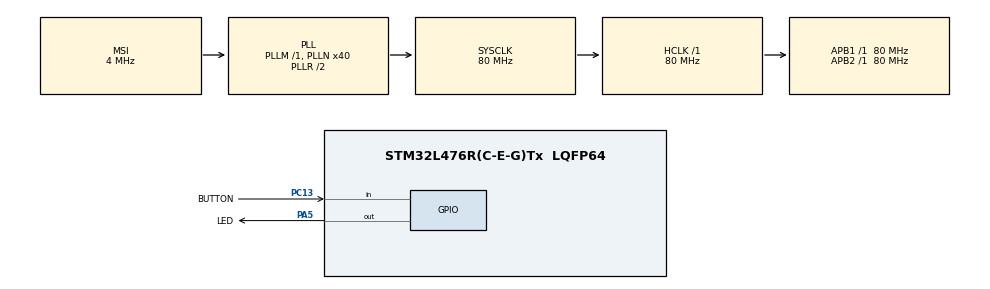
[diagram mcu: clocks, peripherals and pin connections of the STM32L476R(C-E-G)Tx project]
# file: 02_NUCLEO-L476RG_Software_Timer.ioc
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Mcu.Family=STM32L4
Mcu.Name=STM32L476R(C-E-G)Tx
Mcu.Package=LQFP64
Mcu.UserConstants=TIMER_PRESCALER,7999;TIMER_COUNTER,9
NVIC.PriorityGroup=NVIC_PRIORITYGROUP_4
NVIC.TIM6_DAC_IRQn=true\:0\:0\:false\:false\:true\:true\:true
PA5.GPIO_Label=LED
PA5.Signal=GPIO_Output
PC13.GPIO_Label=BUTTON
PC13.Signal=GPIO_Input
ProjectManager.HeapSize=0x200
ProjectManager.StackSize=0x400
ProjectManager.TargetToolchain=STM32CubeIDE
RCC.AHBFreq_Value=80000000
RCC.APB1Freq_Value=80000000
RCC.APB1TimFreq_Value=80000000
RCC.APB2Freq_Value=80000000
RCC.APB2TimFreq_Value=80000000
RCC.CortexFreq_Value=80000000
RCC.HCLKFreq_Value=80000000
RCC.HSE_VALUE=8000000
RCC.HSI_VALUE=16000000
RCC.LSE_VALUE=32768
RCC.MSI_VALUE=4000000
RCC.PLLN=40
RCC.SYSCLKFreq_VALUE=80000000
RCC.SYSCLKSource=RCC_SYSCLKSOURCE_PLLCLK
RCC.VCOOutputFreq_Value=160000000
TIM6.Period=TIMER_COUNTER
TIM6.Prescaler=TIMER_PRESCALER
VP_TIM6_VS_ClockSourceINT.Mode=Enable_Timer
board=custom

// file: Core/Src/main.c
/* USER CODE BEGIN Header */
/**
  ******************************************************************************
  * @file           : main.c
  * @brief          : Main program body
  ******************************************************************************
  * @attention
  *
  * <h2><center>&copy; Copyright (c) 2020 STMicroelectronics.
  * All rights reserved.</center></h2>
  *
  * This software component is licensed by ST under BSD 3-Clause license,
  * the "License"; You may not use this file except in compliance with the
  * License. You may obtain a copy of the License at:
  *                        opensource.org/licenses/BSD-3-Clause
  *
  ******************************************************************************
  */
/* USER CODE END Header */

#include "main.h"
#include "tim.h"
#include "gpio.h"

/* USER CODE BEGIN Includes */
#include "common.h"
#include "software_timer.h"

/* USER CODE END Includes */

/* USER CODE BEGIN PD */
#define APP 4
#if APP == 1
	#define LED_BLINKING_APP		// Software timer array for LED blinking
#elif APP == 2
	#define BUZZER_SOUND_APP		// Software timer for press button and buzzer sound
#elif APP == 3
	#define LCD_BACKLIGHT_APP		// Software timer for LCD backlight ON
#elif APP == 4
	#define UART_TIMEOUT_APP		// Software timer for UART receive timeout
#endif
/* USER CODE END PD */

/* USER CODE BEGIN PV */
#ifdef LED_BLINKING_APP
uint8_t ledSoftwareTimerId[NUM_OF_SOFTWARE_TIMER / 2];
bool ledSoftwareTimerToggle[NUM_OF_SOFTWARE_TIMER / 2];
#endif

#ifdef BUZZER_SOUND_APP
bool isButtonPressed;
uint8_t buzzerTimerId;
bool isBuzzerOn;
#endif

#ifdef LCD_BACKLIGHT_APP
bool isButtonPressed;
uint8_t lcdBackLightTimerId;
bool isBackLightOn;
#endif

#ifdef UART_TIMEOUT_APP
bool isButtonPressed;
uint8_t uartReceiveTimeoutTimerId;
bool isUartReceiveTimeout;
bool isUartAcceptReceive;
#endif
/* USER CODE END PV */

void SystemClock_Config(void);

/* USER CODE BEGIN 0 */
#ifdef LED_BLINKING_APP
/*******************************************************************************
 * @fn      LedTimerCallback
 * @brief   LED timer Callback
 * @paramz  softwareTimerId
 * @return  None
 ******************************************************************************/
void LedTimerCallback(uint8_t softwareTimerId)
{
	ledSoftwareTimerToggle[softwareTimerId] = !ledSoftwareTimerToggle[softwareTimerId];
}
#endif

#ifdef BUZZER_SOUND_APP
/*******************************************************************************
 * @fn      BuzzerTimerStartCallback
 * @brief   Buzzer timer start callback
 * @paramz  softwareTimerId
 * @return  None
 ******************************************************************************/
void BuzzerTimerStartCallback(uint8_t softwareTimerId)
{
	// BuzzerOn();
	isBuzzerOn = true;
	HAL_GPIO_WritePin(LED_GPIO_Port, LED_Pin, GPIO_PIN_SET);
}

/*******************************************************************************
 * @fn      BuzzerTimerCallback
 * @brief   Buzzer timer callback
 * @paramz  softwareTimerId
 * @return  None
 ******************************************************************************/
void BuzzerTimerCallback(uint8_t softwareTimerId)
{
	// BuzzerOff();
	isBuzzerOn = false;
	HAL_GPIO_WritePin(LED_GPIO_Port, LED_Pin, GPIO_PIN_RESET);
}
#endif

#ifdef LCD_BACKLIGHT_APP
/*******************************************************************************
 * @fn      BackLightTimerStartCallback
 * @brief   Back light timer start callback
 * @paramz  softwareTimerId
 * @return  None
 ******************************************************************************/
void BackLightTimerStartCallback(uint8_t softwareTimerId)
{
	// BackLightOn();
	isBackLightOn = true;
}

/*******************************************************************************
 * @fn      BackLightTimerCallback
 * @brief   Back light timer callback
 * @paramz  softwareTimerId
 * @return  None
 ******************************************************************************/
void BackLightTimerCallback(uint8_t softwareTimerId)
{
	// BackLightOff();
	isBackLightOn = false;
}
#endif

#ifdef UART_TIMEOUT_APP
/*******************************************************************************
 * @fn      UartReceiveTimeoutTimerStartCallback
 * @brief   Uart receive timeout timer start callback
 * @paramz  softwareTimerId
 * @return  None
 ******************************************************************************/
void UartReceiveTimeoutTimerStartCallback(uint8_t softwareTimerId)
{
	isUartReceiveTimeout = false;
	isUartAcceptReceive = true;
}

/*******************************************************************************
 * @fn      UartReceiveTimeoutTimerCallback
 * @brief   Uart receive timeout timer callback
 * @paramz  softwareTimerId
 * @return  None
 ******************************************************************************/
void UartReceiveTimeoutTimerCallback(uint8_t softwareTimerId)
{
	isUartReceiveTimeout =true;
	isUartAcceptReceive = false;
}

/*******************************************************************************
 * @fn      UartReceiveTimeoutTimerStopCallback
 * @brief   Uart receive timeout timer stop callback
 * @paramz  softwareTimerId
 * @return  None
 ******************************************************************************/
void UartReceiveTimeoutTimerStopCallback(uint8_t softwareTimerId)
{
	isUartReceiveTimeout = false;
	isUartAcceptReceive = false;
}
#endif
/* USER CODE END 0 */

int main(void)
{
  /* USER CODE BEGIN 1 */
#ifdef LED_BLINKING_APP
  uint8_t i = 0;
#endif

  /* USER CODE END 1 */

  /* MCU Configuration--------------------------------------------------------*/

  /* Reset of all peripherals, Initializes the Flash interface and the Systick. */
  HAL_Init();

  /* Configure the system clock */
  SystemClock_Config();

  /* Initialize all configured peripherals */
  MX_GPIO_Init();
  MX_TIM6_Init();
  /* USER CODE BEGIN 2 */
  // Enable software timer
  sSoftwareTimer.Enable();

#ifdef LED_BLINKING_APP
  for(i = 0; i < NUM_OF_SOFTWARE_TIMER / 2; i++)
  {
	  ledSoftwareTimerId[i] = sSoftwareTimer.Initialize(NULL, LedTimerCallback, NULL, TIMER_PERIODIC_TYPE);
  }
  sSoftwareTimer.Start(ledSoftwareTimerId[0], 100);
  sSoftwareTimer.Start(ledSoftwareTimerId[1], 300);
  sSoftwareTimer.Start(ledSoftwareTimerId[2], 500);
  sSoftwareTimer.Start(ledSoftwareTimerId[3], 700);
  for(;;)
  {
  }
#endif

#ifdef BUZZER_SOUND_APP
  // Normal code
  // BuzzerOn();
  // HAL_Delay(50);
  // BuzzerOff();
  buzzerTimerId = sSoftwareTimer.Initialize(BuzzerTimerStartCallback, BuzzerTimerCallback, NULL, TIMER_ONCE_TYPE);
  // For "SWV Data Trace Timeline Graph" can show data at startup
  isButtonPressed = true;
  isButtonPressed = false;
  isBuzzerOn = true;
  isBuzzerOn = false;
  for(;;)
  {
	  if(HAL_GPIO_ReadPin(BUTTON_GPIO_Port, BUTTON_Pin) == GPIO_PIN_RESET && !isButtonPressed)
	  {
		  isButtonPressed = true;
		  sSoftwareTimer.Start(buzzerTimerId, 50);
	  }
	  else if(HAL_GPIO_ReadPin(BUTTON_GPIO_Port, BUTTON_Pin) == GPIO_PIN_SET && isButtonPressed)
	  {
		  isButtonPressed = false;
	  }
  }
#endif
#ifdef LCD_BACKLIGHT_APP
  lcdBackLightTimerId = sSoftwareTimer.Initialize(BackLightTimerStartCallback, BackLightTimerCallback, NULL, TIMER_ONCE_TYPE);
  // For "SWV Data Trace Timeline Graph" can show data at startup
  isButtonPressed = true;
  isButtonPressed = false;
  isBackLightOn = true;
  isBackLightOn = false;
  for(;;)
  {
	  if(HAL_GPIO_ReadPin(BUTTON_GPIO_Port, BUTTON_Pin) == GPIO_PIN_RESET && !isButtonPressed)
	  {
		  isButtonPressed = true;
		  sSoftwareTimer.Start(lcdBackLightTimerId, 2000);
	  }
	  else if(HAL_GPIO_ReadPin(BUTTON_GPIO_Port, BUTTON_Pin) == GPIO_PIN_SET && isButtonPressed)
	  {
		  isButtonPressed = false;
	  }
  }
#endif

#ifdef UART_TIMEOUT_APP
  isButtonPressed = true;
  isButtonPressed = false;
  isUartReceiveTimeout = true;
  isUartAcceptReceive = true;
  isUartReceiveTimeout = false;
  isUartAcceptReceive = false;
  uartReceiveTimeoutTimerId = sSoftwareTimer.Initialize(UartReceiveTimeoutTimerStartCallback, UartReceiveTimeoutTimerCallback, UartReceiveTimeoutTimerStopCallback, TIMER_ONCE_TYPE);
  for(;;)
  {
	  // Check button press
	  if(HAL_GPIO_ReadPin(BUTTON_GPIO_Port, BUTTON_Pin) == GPIO_PIN_RESET && !isButtonPressed)
	  {
		  isButtonPressed = true;
		  if(!isUartAcceptReceive)
		  {
			  sSoftwareTimer.Start(uartReceiveTimeoutTimerId, 5000);
		  }
		  else
		  {
			  sSoftwareTimer.Stop(uartReceiveTimeoutTimerId);
		  }
	  }
	  else if(HAL_GPIO_ReadPin(BUTTON_GPIO_Port, BUTTON_Pin) == GPIO_PIN_SET)
	  {
		  isButtonPressed = false;
	  }
  }
#endif
/* USER CODE END 2 */

  /* Infinite loop */
  while (1)
  {

  }
}

void SystemClock_Config(void)
{
  RCC_OscInitTypeDef RCC_OscInitStruct = {0};
  RCC_ClkInitTypeDef RCC_ClkInitStruct = {0};

  /** Initializes the CPU, AHB and APB busses clocks
  */
  RCC_OscInitStruct.OscillatorType = RCC_OSCILLATORTYPE_MSI;
  RCC_OscInitStruct.MSIState = RCC_MSI_ON;
  RCC_OscInitStruct.MSICalibrationValue = 0;
  RCC_OscInitStruct.MSIClockRange = RCC_MSIRANGE_6;
  RCC_OscInitStruct.PLL.PLLState = RCC_PLL_ON;
  RCC_OscInitStruct.PLL.PLLSource = RCC_PLLSOURCE_MSI;
  RCC_OscInitStruct.PLL.PLLM = 1;
  RCC_OscInitStruct.PLL.PLLN = 40;
  RCC_OscInitStruct.PLL.PLLP = RCC_PLLP_DIV7;
  RCC_OscInitStruct.PLL.PLLQ = RCC_PLLQ_DIV2;
  RCC_OscInitStruct.PLL.PLLR = RCC_PLLR_DIV2;
  if (HAL_RCC_OscConfig(&RCC_OscInitStruct) != HAL_OK)
  {
    Error_Handler();
  }
  /** Initializes the CPU, AHB and APB busses clocks
  */
  RCC_ClkInitStruct.ClockType = RCC_CLOCKTYPE_HCLK|RCC_CLOCKTYPE_SYSCLK
                              |RCC_CLOCKTYPE_PCLK1|RCC_CLOCKTYPE_PCLK2;
  RCC_ClkInitStruct.SYSCLKSource = RCC_SYSCLKSOURCE_PLLCLK;
  RCC_ClkInitStruct.AHBCLKDivider = RCC_SYSCLK_DIV1;
  RCC_ClkInitStruct.APB1CLKDivider = RCC_HCLK_DIV1;
  RCC_ClkInitStruct.APB2CLKDivider = RCC_HCLK_DIV1;

  if (HAL_RCC_ClockConfig(&RCC_ClkInitStruct, FLASH_LATENCY_4) != HAL_OK)
  {
    Error_Handler();
  }
  /** Configure the main internal regulator output voltage
  */
  if (HAL_PWREx_ControlVoltageScaling(PWR_REGULATOR_VOLTAGE_SCALE1) != HAL_OK)
  {
    Error_Handler();
  }
}

void Error_Handler(void)
{
}

/************************ (C) COPYRIGHT STMicroelectronics *****END OF FILE****/
